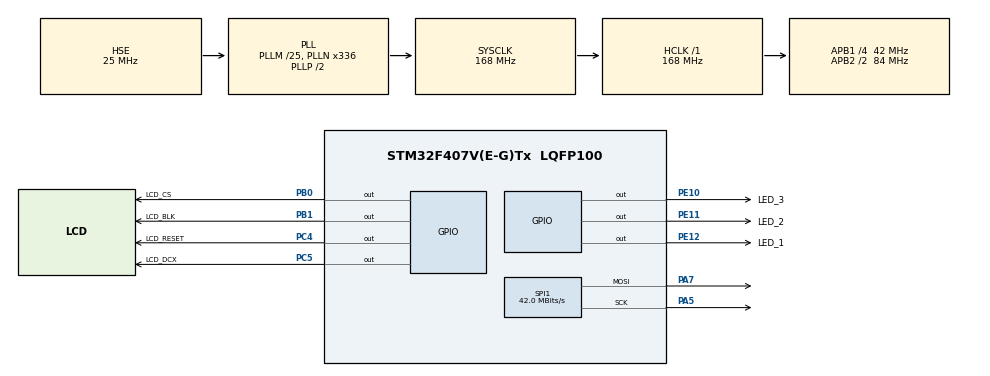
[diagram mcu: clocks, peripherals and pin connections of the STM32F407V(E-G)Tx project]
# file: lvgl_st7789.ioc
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Dma.Request0=SPI1_TX
Dma.SPI1_TX.0.Direction=DMA_MEMORY_TO_PERIPH
Dma.SPI1_TX.0.FIFOMode=DMA_FIFOMODE_ENABLE
Dma.SPI1_TX.0.FIFOThreshold=DMA_FIFO_THRESHOLD_FULL
Dma.SPI1_TX.0.Instance=DMA2_Stream3
Dma.SPI1_TX.0.MemBurst=DMA_MBURST_SINGLE
Dma.SPI1_TX.0.MemDataAlignment=DMA_MDATAALIGN_HALFWORD
Dma.SPI1_TX.0.MemInc=DMA_MINC_ENABLE
Dma.SPI1_TX.0.Mode=DMA_NORMAL
Dma.SPI1_TX.0.PeriphBurst=DMA_PBURST_SINGLE
Dma.SPI1_TX.0.PeriphDataAlignment=DMA_PDATAALIGN_HALFWORD
Dma.SPI1_TX.0.PeriphInc=DMA_PINC_DISABLE
Dma.SPI1_TX.0.Priority=DMA_PRIORITY_LOW
Mcu.Family=STM32F4
Mcu.Name=STM32F407V(E-G)Tx
Mcu.Package=LQFP100
NVIC.DMA2_Stream3_IRQn=true\:0\:0\:false\:false\:true\:false\:true\:true
NVIC.PriorityGroup=NVIC_PRIORITYGROUP_4
NVIC.SPI1_IRQn=true\:0\:0\:false\:false\:true\:true\:true\:true
PA13.Mode=Serial_Wire
PA13.Signal=SYS_JTMS-SWDIO
PA14.Mode=Serial_Wire
PA14.Signal=SYS_JTCK-SWCLK
PA5.Mode=TX_Only_Simplex_Unidirect_Master
PA5.Signal=SPI1_SCK
PA7.Mode=TX_Only_Simplex_Unidirect_Master
PA7.Signal=SPI1_MOSI
PB0.GPIO_Label=LCD_CS
PB0.GPIO_Speed=GPIO_SPEED_FREQ_VERY_HIGH
PB0.PinState=GPIO_PIN_SET
PB0.Signal=GPIO_Output
PB1.GPIO_Label=LCD_BLK
PB1.Signal=GPIO_Output
PC4.GPIO_Label=LCD_RESET
PC4.Signal=GPIO_Output
PC5.GPIO_Label=LCD_DCX
PC5.GPIO_Speed=GPIO_SPEED_FREQ_VERY_HIGH
PC5.Signal=GPIO_Output
PE10.GPIO_Label=LED_3
PE10.PinState=GPIO_PIN_SET
PE10.Signal=GPIO_Output
PE11.GPIO_Label=LED_2
PE11.PinState=GPIO_PIN_SET
PE11.Signal=GPIO_Output
PE12.GPIO_Label=LED_1
PE12.PinState=GPIO_PIN_SET
PE12.Signal=GPIO_Output
PH0-OSC_IN.Mode=HSE-External-Oscillator
PH0-OSC_IN.Signal=RCC_OSC_IN
PH1-OSC_OUT.Mode=HSE-External-Oscillator
PH1-OSC_OUT.Signal=RCC_OSC_OUT
ProjectManager.HeapSize=0x800
ProjectManager.StackSize=0x2000
ProjectManager.TargetToolchain=STM32CubeIDE
RCC.48MHZClocksFreq_Value=84000000
RCC.AHBFreq_Value=168000000
RCC.APB1CLKDivider=RCC_HCLK_DIV4
RCC.APB1Freq_Value=42000000
RCC.APB1TimFreq_Value=84000000
RCC.APB2CLKDivider=RCC_HCLK_DIV2
RCC.APB2Freq_Value=84000000
RCC.APB2TimFreq_Value=168000000
RCC.CortexFreq_Value=168000000
RCC.HCLKFreq_Value=168000000
RCC.HSE_VALUE=25000000
RCC.HSI_VALUE=16000000
RCC.LSE_VALUE=32768
RCC.PLLM=25
RCC.PLLN=336
RCC.PLLSourceVirtual=RCC_PLLSOURCE_HSE
RCC.SYSCLKFreq_VALUE=168000000
RCC.SYSCLKSource=RCC_SYSCLKSOURCE_PLLCLK
RCC.VCOOutputFreq_Value=336000000
SPI1.CalculateBaudRate=42.0 MBits/s
SPI1.Direction=SPI_DIRECTION_2LINES
SPI1.Mode=SPI_MODE_MASTER
SPI1.VirtualType=VM_MASTER
STMicroelectronics.X-CUBE-DISPLAY.3.0.0_IsPackSelfContextualization=true
board=custom

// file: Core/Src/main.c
/* USER CODE BEGIN Header */
/**
  ******************************************************************************
  * @file           : main.c
  * @brief          : Main program body
  ******************************************************************************
  * @attention
  *
  * Copyright (c) 2024 STMicroelectronics.
  * All rights reserved.
  *
  * This software is licensed under terms that can be found in the LICENSE file
  * in the root directory of this software component.
  * If no LICENSE file comes with this software, it is provided AS-IS.
  *
  ******************************************************************************
  */
/* USER CODE END Header */
#include "main.h"
#include "dma.h"
#include "spi.h"
#include "gpio.h"

/* USER CODE BEGIN Includes */
#include "lv_port_disp.h"
#include "lv_examples.h"
#include "lv_demos.h"
/* USER CODE END Includes */

void SystemClock_Config(void);

int main(void)
{

  /* MCU Configuration--------------------------------------------------------*/

  /* Reset of all peripherals, Initializes the Flash interface and the Systick. */
  HAL_Init();

  /* Configure the system clock */
  SystemClock_Config();

  /* Initialize all configured peripherals */
  MX_GPIO_Init();
  MX_DMA_Init();
  MX_SPI1_Init();
  /* USER CODE BEGIN 2 */
  LED_1_ON();
  HAL_GPIO_WritePin(LCD_BLK_GPIO_Port, LCD_BLK_Pin, GPIO_PIN_SET);

  lv_init();
  lv_port_disp_init();
  lv_demo_benchmark();

  /* USER CODE END 2 */

  /* Infinite loop */
  while (1)
  {

    /* USER CODE BEGIN 3 */
	lv_timer_periodic_handler();
  }
  /* USER CODE END 3 */
}

void SystemClock_Config(void)
{
  RCC_OscInitTypeDef RCC_OscInitStruct = {0};
  RCC_ClkInitTypeDef RCC_ClkInitStruct = {0};

  /** Configure the main internal regulator output voltage
  */
  __HAL_RCC_PWR_CLK_ENABLE();
  __HAL_PWR_VOLTAGESCALING_CONFIG(PWR_REGULATOR_VOLTAGE_SCALE1);

  /** Initializes the RCC Oscillators according to the specified parameters
  * in the RCC_OscInitTypeDef structure.
  */
  RCC_OscInitStruct.OscillatorType = RCC_OSCILLATORTYPE_HSE;
  RCC_OscInitStruct.HSEState = RCC_HSE_ON;
  RCC_OscInitStruct.PLL.PLLState = RCC_PLL_ON;
  RCC_OscInitStruct.PLL.PLLSource = RCC_PLLSOURCE_HSE;
  RCC_OscInitStruct.PLL.PLLM = 25;
  RCC_OscInitStruct.PLL.PLLN = 336;
  RCC_OscInitStruct.PLL.PLLP = RCC_PLLP_DIV2;
  RCC_OscInitStruct.PLL.PLLQ = 4;
  if (HAL_RCC_OscConfig(&RCC_OscInitStruct) != HAL_OK)
  {
    Error_Handler();
  }

  /** Initializes the CPU, AHB and APB buses clocks
  */
  RCC_ClkInitStruct.ClockType = RCC_CLOCKTYPE_HCLK|RCC_CLOCKTYPE_SYSCLK
                              |RCC_CLOCKTYPE_PCLK1|RCC_CLOCKTYPE_PCLK2;
  RCC_ClkInitStruct.SYSCLKSource = RCC_SYSCLKSOURCE_PLLCLK;
  RCC_ClkInitStruct.AHBCLKDivider = RCC_SYSCLK_DIV1;
  RCC_ClkInitStruct.APB1CLKDivider = RCC_HCLK_DIV4;
  RCC_ClkInitStruct.APB2CLKDivider = RCC_HCLK_DIV2;

  if (HAL_RCC_ClockConfig(&RCC_ClkInitStruct, FLASH_LATENCY_5) != HAL_OK)
  {
    Error_Handler();
  }
}

void Error_Handler(void)
{
  __disable_irq();
  while (1)
  {
  }
}
